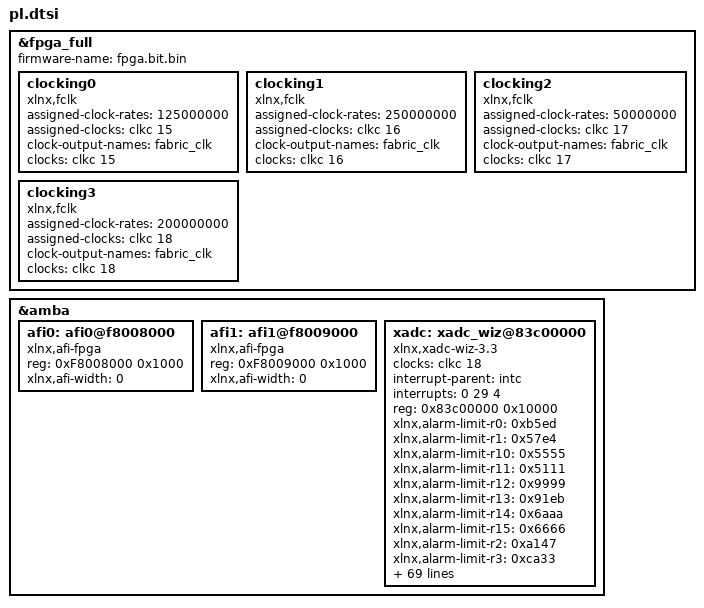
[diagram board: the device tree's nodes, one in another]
/*
 * CAUTION: This file is automatically generated by Xilinx.
 * Version: XSCT 2024.2
 * Today is: Thu Jul 17 21:00:14 2025
 */


/dts-v1/;
/plugin/;
&fpga_full {
	firmware-name = "fpga.bit.bin";
	clocking0: clocking0 {
		#clock-cells = <0>;
		assigned-clock-rates = <125000000>;
		assigned-clocks = <&clkc 15>;
		clock-output-names = "fabric_clk";
		clocks = <&clkc 15>;
		compatible = "xlnx,fclk";
	};
	clocking1: clocking1 {
		#clock-cells = <0>;
		assigned-clock-rates = <250000000>;
		assigned-clocks = <&clkc 16>;
		clock-output-names = "fabric_clk";
		clocks = <&clkc 16>;
		compatible = "xlnx,fclk";
	};
	clocking2: clocking2 {
		#clock-cells = <0>;
		assigned-clock-rates = <50000000>;
		assigned-clocks = <&clkc 17>;
		clock-output-names = "fabric_clk";
		clocks = <&clkc 17>;
		compatible = "xlnx,fclk";
	};
	clocking3: clocking3 {
		#clock-cells = <0>;
		assigned-clock-rates = <200000000>;
		assigned-clocks = <&clkc 18>;
		clock-output-names = "fabric_clk";
		clocks = <&clkc 18>;
		compatible = "xlnx,fclk";
	};
};
&amba {
	//#address-cells = <1>;
	//#size-cells = <1>;
	afi0: afi0@f8008000 {
		//#address-cells = <1>;
		//#size-cells = <0>;
		compatible = "xlnx,afi-fpga";
		reg = <0xF8008000 0x1000>;
		xlnx,afi-width = <0>;
	};
	afi1: afi1@f8009000 {
		//#address-cells = <1>;
		//#size-cells = <0>;
		compatible = "xlnx,afi-fpga";
		reg = <0xF8009000 0x1000>;
		xlnx,afi-width = <0>;
	};
	xadc: xadc_wiz@83c00000 {
		clock-names = "s_axi_aclk";
		clocks = <&clkc 18>;
		compatible = "xlnx,xadc-wiz-3.3", "xlnx,axi-xadc-1.00.a";
		interrupt-names = "ip2intc_irpt";
		interrupt-parent = <&intc>;
		interrupts = <0 29 4>;
		reg = <0x83c00000 0x10000>;
		xlnx,alarm-limit-r0 = <0xb5ed>;
		xlnx,alarm-limit-r1 = <0x57e4>;
		xlnx,alarm-limit-r10 = <0x5555>;
		xlnx,alarm-limit-r11 = <0x5111>;
		xlnx,alarm-limit-r12 = <0x9999>;
		xlnx,alarm-limit-r13 = <0x91eb>;
		xlnx,alarm-limit-r14 = <0x6aaa>;
		xlnx,alarm-limit-r15 = <0x6666>;
		xlnx,alarm-limit-r2 = <0xa147>;
		xlnx,alarm-limit-r3 = <0xca33>;
		xlnx,alarm-limit-r4 = <0xa93a>;
		xlnx,alarm-limit-r5 = <0x52c6>;
		xlnx,alarm-limit-r6 = <0x9555>;
		xlnx,alarm-limit-r7 = <0xae4e>;
		xlnx,alarm-limit-r8 = <0x5999>;
		xlnx,alarm-limit-r9 = <0x5111>;
		xlnx,configuration-r0 = <0x0>;
		xlnx,configuration-r1 = <0x8100>;
		xlnx,configuration-r2 = <0x400>;
		xlnx,dclk-frequency = <0x64>;
		xlnx,external-mux = "none";
		xlnx,external-mux-channel = "VP_VN";
		xlnx,external-muxaddr-enable = <0x0>;
		xlnx,fifo-depth = <0x7>;
		xlnx,has-axi = <0x1>;
		xlnx,has-axi4stream = <0x0>;
		xlnx,has-busy = <0x1>;
		xlnx,has-channel = <0x1>;
		xlnx,has-convst = <0x0>;
		xlnx,has-convstclk = <0x0>;
		xlnx,has-dclk = <0x1>;
		xlnx,has-drp = <0x0>;
		xlnx,has-eoc = <0x1>;
		xlnx,has-eos = <0x1>;
		xlnx,has-external-mux = <0x0>;
		xlnx,has-jtagbusy = <0x0>;
		xlnx,has-jtaglocked = <0x0>;
		xlnx,has-jtagmodified = <0x0>;
		xlnx,has-ot-alarm = <0x1>;
		xlnx,has-reset = <0x0>;
		xlnx,has-temp-bus = <0x0>;
		xlnx,has-user-temp-alarm = <0x1>;
		xlnx,has-vbram-alarm = <0x0>;
		xlnx,has-vccaux-alarm = <0x1>;
		xlnx,has-vccddro-alarm = <0x1>;
		xlnx,has-vccint-alarm = <0x1>;
		xlnx,has-vccpaux-alarm = <0x1>;
		xlnx,has-vccpint-alarm = <0x1>;
		xlnx,has-vn = <0x1>;
		xlnx,has-vp = <0x1>;
		xlnx,include-intr = <0x1>;
		xlnx,sampling-rate = "961538.4615384615";
		xlnx,sequence-r0 = <0x800>;
		xlnx,sequence-r1 = <0x303>;
		xlnx,sequence-r2 = <0x0>;
		xlnx,sequence-r3 = <0x0>;
		xlnx,sequence-r4 = <0x0>;
		xlnx,sequence-r5 = <0x0>;
		xlnx,sequence-r6 = <0x0>;
		xlnx,sequence-r7 = <0x0>;
		xlnx,sim-file-name = "design";
		xlnx,sim-file-rel-path = "./";
		xlnx,sim-file-sel = "Default";
		xlnx,vaux0 = <0x1>;
		xlnx,vaux1 = <0x1>;
		xlnx,vaux10 = <0x0>;
		xlnx,vaux11 = <0x0>;
		xlnx,vaux12 = <0x0>;
		xlnx,vaux13 = <0x0>;
		xlnx,vaux14 = <0x0>;
		xlnx,vaux15 = <0x0>;
		xlnx,vaux2 = <0x0>;
		xlnx,vaux3 = <0x0>;
		xlnx,vaux4 = <0x0>;
		xlnx,vaux5 = <0x0>;
		xlnx,vaux6 = <0x0>;
		xlnx,vaux7 = <0x0>;
		xlnx,vaux8 = <0x1>;
		xlnx,vaux9 = <0x1>;
	};
};
